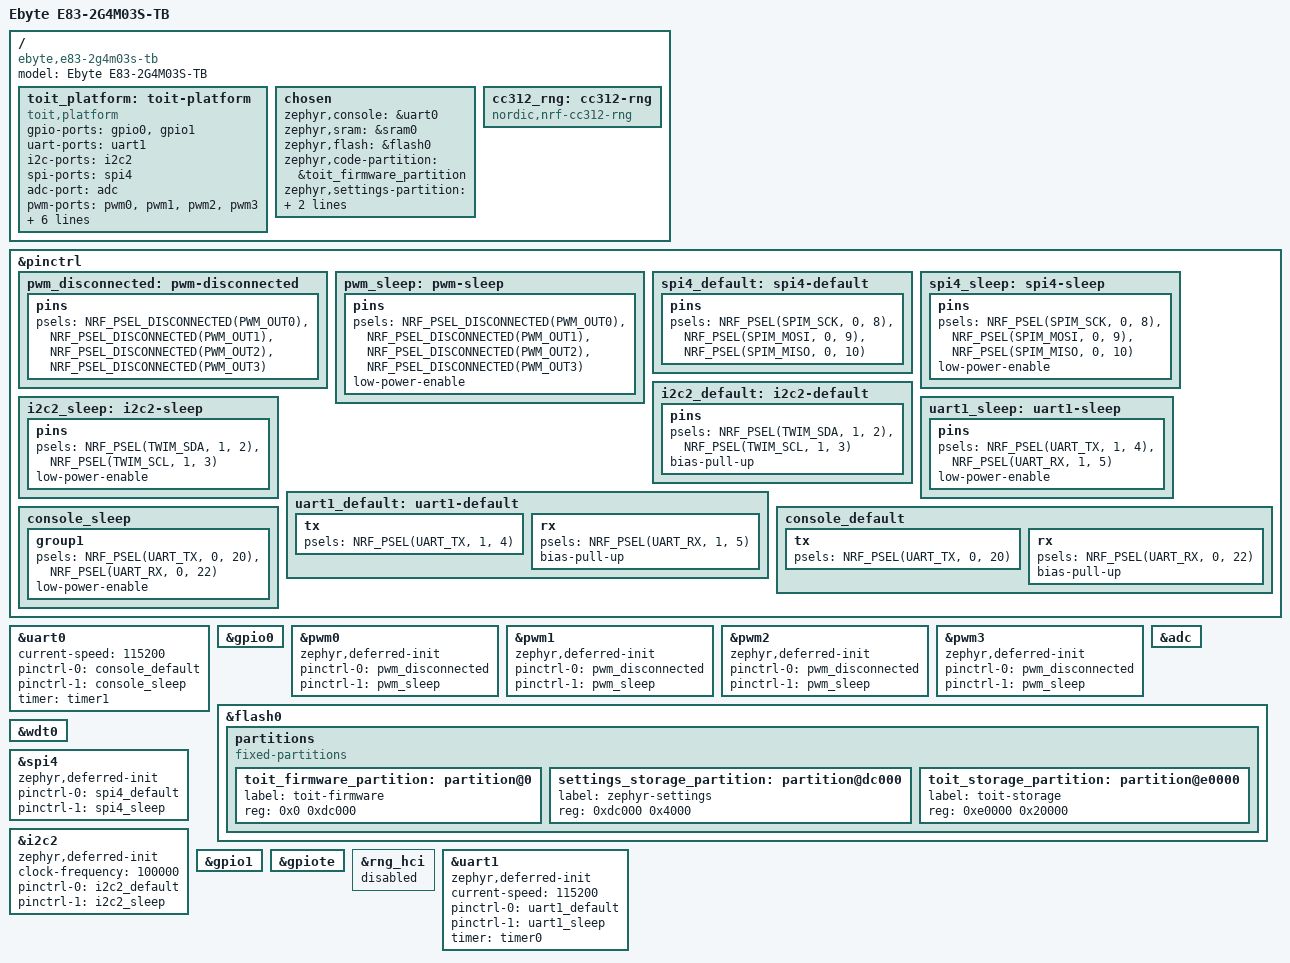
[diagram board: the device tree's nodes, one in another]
/* Copyright (C) 2026 Toit contributors.
 * SPDX-License-Identifier: Apache-2.0 */
/dts-v1/;
#include <nordic/nrf5340_cpuapp_qkaa.dtsi>
#include <zephyr/dt-bindings/pinctrl/nrf-pinctrl.h>
#include <zephyr/dt-bindings/adc/nrf-saadc.h>
/delete-node/ &ipc0;

/ {
  model = "Ebyte E83-2G4M03S-TB";
  compatible = "ebyte,e83-2g4m03s-tb";
  toit_platform: toit-platform {
    compatible = "toit,platform";
    gpio-ports = <&gpio0 &gpio1>;
    uart-ports = <&uart1>;
    i2c-ports = <&i2c2>;
    spi-ports = <&spi4>;
    adc-port = <&adc>;
    pwm-ports = <&pwm0 &pwm1 &pwm2 &pwm3>;
    watchdog-port = <&wdt0>;
    storage-partition = <&toit_storage_partition>;
    adc-pins = <4 5 6 7 25 26 27 28>;
    adc-inputs = <NRF_SAADC_AIN0 NRF_SAADC_AIN1 NRF_SAADC_AIN2 NRF_SAADC_AIN3
                  NRF_SAADC_AIN4 NRF_SAADC_AIN5 NRF_SAADC_AIN6 NRF_SAADC_AIN7>;
    /* Crystal, NFC, reset, and USB-TTL console pins. */
    reserved-pins = <0 1 2 3 18 20 22>;
  };
  chosen {
    zephyr,console = &uart0;
    zephyr,sram = &sram0;
    zephyr,flash = &flash0;
    zephyr,code-partition = &toit_firmware_partition;
    zephyr,settings-partition = &settings_storage_partition;
    zephyr,entropy = &cc312_rng;
  };
  cc312_rng: cc312-rng { compatible = "nordic,nrf-cc312-rng"; };
};

&pinctrl {
  pwm_disconnected: pwm-disconnected {
    pins { psels = <NRF_PSEL_DISCONNECTED(PWM_OUT0)>, <NRF_PSEL_DISCONNECTED(PWM_OUT1)>,
                   <NRF_PSEL_DISCONNECTED(PWM_OUT2)>, <NRF_PSEL_DISCONNECTED(PWM_OUT3)>; };
  };
  pwm_sleep: pwm-sleep {
    pins { psels = <NRF_PSEL_DISCONNECTED(PWM_OUT0)>, <NRF_PSEL_DISCONNECTED(PWM_OUT1)>,
                   <NRF_PSEL_DISCONNECTED(PWM_OUT2)>, <NRF_PSEL_DISCONNECTED(PWM_OUT3)>;
           low-power-enable; };
  };
  spi4_default: spi4-default {
    pins { psels = <NRF_PSEL(SPIM_SCK, 0, 8)>, <NRF_PSEL(SPIM_MOSI, 0, 9)>,
                   <NRF_PSEL(SPIM_MISO, 0, 10)>; };
  };
  spi4_sleep: spi4-sleep {
    pins { psels = <NRF_PSEL(SPIM_SCK, 0, 8)>, <NRF_PSEL(SPIM_MOSI, 0, 9)>,
                   <NRF_PSEL(SPIM_MISO, 0, 10)>; low-power-enable; };
  };
  i2c2_default: i2c2-default {
    pins { psels = <NRF_PSEL(TWIM_SDA, 1, 2)>, <NRF_PSEL(TWIM_SCL, 1, 3)>;
           bias-pull-up; };
  };
  i2c2_sleep: i2c2-sleep {
    pins { psels = <NRF_PSEL(TWIM_SDA, 1, 2)>, <NRF_PSEL(TWIM_SCL, 1, 3)>;
           low-power-enable; };
  };
  uart1_default: uart1-default {
    tx { psels = <NRF_PSEL(UART_TX, 1, 4)>; };
    rx { psels = <NRF_PSEL(UART_RX, 1, 5)>; bias-pull-up; };
  };
  uart1_sleep: uart1-sleep {
    pins { psels = <NRF_PSEL(UART_TX, 1, 4)>, <NRF_PSEL(UART_RX, 1, 5)>;
           low-power-enable; };
  };
  console_default: console_default {
    tx { psels = <NRF_PSEL(UART_TX, 0, 20)>; };
    rx { psels = <NRF_PSEL(UART_RX, 0, 22)>; bias-pull-up; };
  };
  console_sleep: console_sleep {
    group1 {
      psels = <NRF_PSEL(UART_TX, 0, 20)>, <NRF_PSEL(UART_RX, 0, 22)>;
      low-power-enable;
    };
  };
};
&uart0 {
  status = "okay";
  current-speed = <115200>;
  pinctrl-0 = <&console_default>;
  pinctrl-1 = <&console_sleep>;
  pinctrl-names = "default", "sleep";
  timer = <&timer1>;
};
&gpio0 { status = "okay"; };
&pwm0 {
  status = "okay";
  zephyr,deferred-init;
  pinctrl-0 = <&pwm_disconnected>;
  pinctrl-1 = <&pwm_sleep>;
  pinctrl-names = "default", "sleep";
};
&pwm1 {
  status = "okay";
  zephyr,deferred-init;
  pinctrl-0 = <&pwm_disconnected>;
  pinctrl-1 = <&pwm_sleep>;
  pinctrl-names = "default", "sleep";
};
&pwm2 {
  status = "okay";
  zephyr,deferred-init;
  pinctrl-0 = <&pwm_disconnected>;
  pinctrl-1 = <&pwm_sleep>;
  pinctrl-names = "default", "sleep";
};
&pwm3 {
  status = "okay";
  zephyr,deferred-init;
  pinctrl-0 = <&pwm_disconnected>;
  pinctrl-1 = <&pwm_sleep>;
  pinctrl-names = "default", "sleep";
};
&adc { status = "okay"; };
&flash0 {
  partitions {
    compatible = "fixed-partitions";
    #address-cells = <1>;
    #size-cells = <1>;
    toit_firmware_partition: partition@0 {
      label = "toit-firmware";
      reg = <0x0 0xdc000>;
    };
    settings_storage_partition: partition@dc000 {
      label = "zephyr-settings";
      reg = <0xdc000 0x4000>;
    };
    toit_storage_partition: partition@e0000 {
      label = "toit-storage";
      reg = <0xe0000 0x20000>;
    };
  };
};
&wdt0 { status = "okay"; };
&spi4 {
  status = "okay";
  zephyr,deferred-init;
  pinctrl-0 = <&spi4_default>;
  pinctrl-1 = <&spi4_sleep>;
  pinctrl-names = "default", "sleep";
};
&i2c2 {
  status = "okay";
  zephyr,deferred-init;
  clock-frequency = <100000>;
  pinctrl-0 = <&i2c2_default>;
  pinctrl-1 = <&i2c2_sleep>;
  pinctrl-names = "default", "sleep";
};
&gpio1 { status = "okay"; };
&gpiote { status = "okay"; };
&rng_hci { status = "disabled"; };

&uart1 {
  status = "okay";
  zephyr,deferred-init;
  current-speed = <115200>;
  pinctrl-0 = <&uart1_default>;
  pinctrl-1 = <&uart1_sleep>;
  pinctrl-names = "default", "sleep";
  timer = <&timer0>;
};
